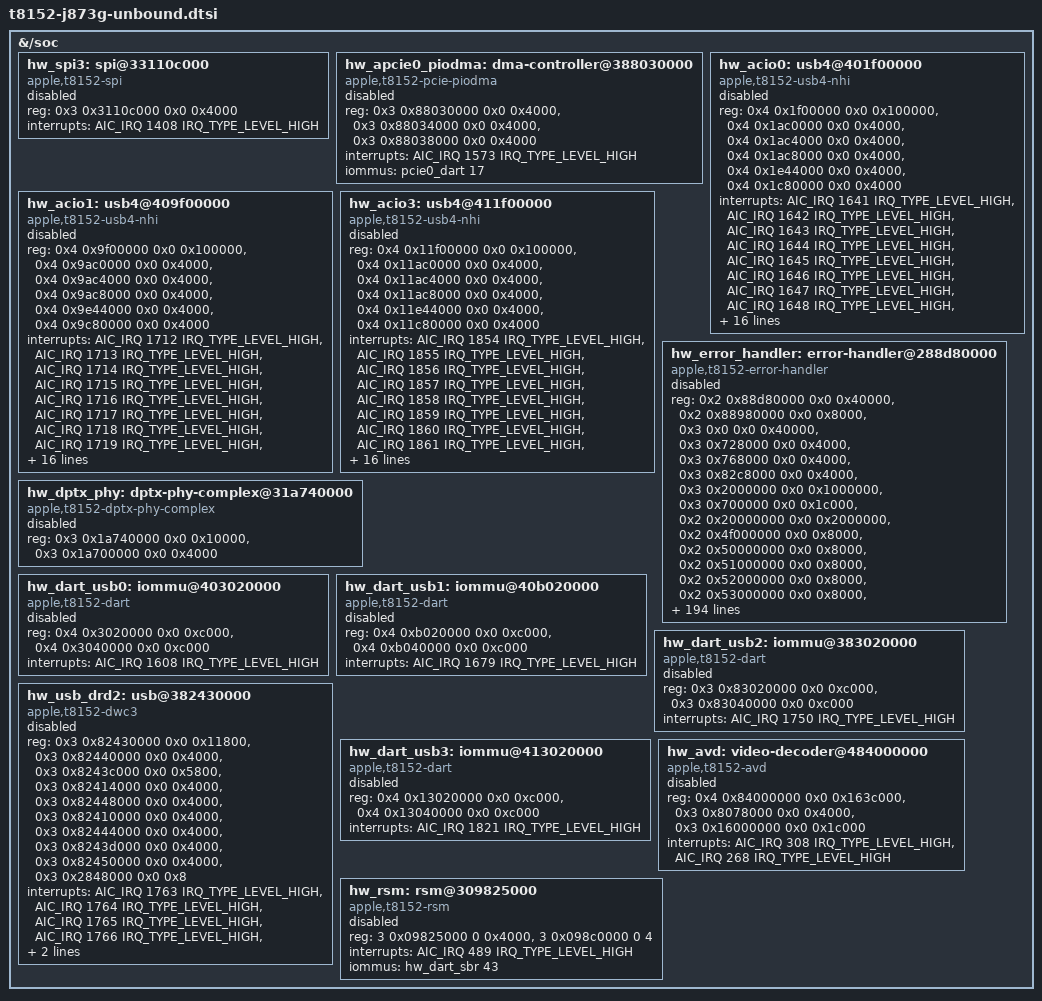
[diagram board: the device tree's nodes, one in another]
#include "t8152-peripherals.dtsi"

// SPDX-License-Identifier: GPL-2.0+ OR MIT
/* Register and interrupt resources; ownership-sensitive blocks stay disabled. */

&{/soc} {

	hw_spi3: spi@33110c000 {
		compatible = "apple,t8152-spi", "apple,spi";
		reg = <0x3 0x3110c000 0x0 0x4000>;
		interrupts = <AIC_IRQ 1408 IRQ_TYPE_LEVEL_HIGH>;
		status = "disabled";
	};

	hw_apcie0_piodma: dma-controller@388030000 {
		compatible = "apple,t8152-pcie-piodma", "apple,pcie-piodma";
		reg = <0x3 0x88030000 0x0 0x4000>,
		      <0x3 0x88034000 0x0 0x4000>,
		      <0x3 0x88038000 0x0 0x4000>;
		interrupts = <AIC_IRQ 1573 IRQ_TYPE_LEVEL_HIGH>;
		iommus = <&pcie0_dart 17>;
		status = "disabled";
	};

	hw_acio0: usb4@401f00000 {
		compatible = "apple,t8152-usb4-nhi", "apple,usb4-nhi";
		reg = <0x4 0x1f00000 0x0 0x100000>,
		      <0x4 0x1ac0000 0x0 0x4000>,
		      <0x4 0x1ac4000 0x0 0x4000>,
		      <0x4 0x1ac8000 0x0 0x4000>,
		      <0x4 0x1e44000 0x0 0x4000>,
		      <0x4 0x1c80000 0x0 0x4000>;
		interrupts = <AIC_IRQ 1641 IRQ_TYPE_LEVEL_HIGH>,
			     <AIC_IRQ 1642 IRQ_TYPE_LEVEL_HIGH>,
			     <AIC_IRQ 1643 IRQ_TYPE_LEVEL_HIGH>,
			     <AIC_IRQ 1644 IRQ_TYPE_LEVEL_HIGH>,
			     <AIC_IRQ 1645 IRQ_TYPE_LEVEL_HIGH>,
			     <AIC_IRQ 1646 IRQ_TYPE_LEVEL_HIGH>,
			     <AIC_IRQ 1647 IRQ_TYPE_LEVEL_HIGH>,
			     <AIC_IRQ 1648 IRQ_TYPE_LEVEL_HIGH>,
			     <AIC_IRQ 1649 IRQ_TYPE_LEVEL_HIGH>,
			     <AIC_IRQ 1650 IRQ_TYPE_LEVEL_HIGH>,
			     <AIC_IRQ 1651 IRQ_TYPE_LEVEL_HIGH>,
			     <AIC_IRQ 1652 IRQ_TYPE_LEVEL_HIGH>,
			     <AIC_IRQ 1629 IRQ_TYPE_LEVEL_HIGH>,
			     <AIC_IRQ 1630 IRQ_TYPE_LEVEL_HIGH>,
			     <AIC_IRQ 1631 IRQ_TYPE_LEVEL_HIGH>,
			     <AIC_IRQ 1632 IRQ_TYPE_LEVEL_HIGH>,
			     <AIC_IRQ 1633 IRQ_TYPE_LEVEL_HIGH>,
			     <AIC_IRQ 1634 IRQ_TYPE_LEVEL_HIGH>,
			     <AIC_IRQ 1635 IRQ_TYPE_LEVEL_HIGH>,
			     <AIC_IRQ 1636 IRQ_TYPE_LEVEL_HIGH>,
			     <AIC_IRQ 1637 IRQ_TYPE_LEVEL_HIGH>,
			     <AIC_IRQ 1638 IRQ_TYPE_LEVEL_HIGH>,
			     <AIC_IRQ 1639 IRQ_TYPE_LEVEL_HIGH>,
			     <AIC_IRQ 1640 IRQ_TYPE_LEVEL_HIGH>;
		status = "disabled";
	};

	hw_acio1: usb4@409f00000 {
		compatible = "apple,t8152-usb4-nhi", "apple,usb4-nhi";
		reg = <0x4 0x9f00000 0x0 0x100000>,
		      <0x4 0x9ac0000 0x0 0x4000>,
		      <0x4 0x9ac4000 0x0 0x4000>,
		      <0x4 0x9ac8000 0x0 0x4000>,
		      <0x4 0x9e44000 0x0 0x4000>,
		      <0x4 0x9c80000 0x0 0x4000>;
		interrupts = <AIC_IRQ 1712 IRQ_TYPE_LEVEL_HIGH>,
			     <AIC_IRQ 1713 IRQ_TYPE_LEVEL_HIGH>,
			     <AIC_IRQ 1714 IRQ_TYPE_LEVEL_HIGH>,
			     <AIC_IRQ 1715 IRQ_TYPE_LEVEL_HIGH>,
			     <AIC_IRQ 1716 IRQ_TYPE_LEVEL_HIGH>,
			     <AIC_IRQ 1717 IRQ_TYPE_LEVEL_HIGH>,
			     <AIC_IRQ 1718 IRQ_TYPE_LEVEL_HIGH>,
			     <AIC_IRQ 1719 IRQ_TYPE_LEVEL_HIGH>,
			     <AIC_IRQ 1720 IRQ_TYPE_LEVEL_HIGH>,
			     <AIC_IRQ 1721 IRQ_TYPE_LEVEL_HIGH>,
			     <AIC_IRQ 1722 IRQ_TYPE_LEVEL_HIGH>,
			     <AIC_IRQ 1723 IRQ_TYPE_LEVEL_HIGH>,
			     <AIC_IRQ 1700 IRQ_TYPE_LEVEL_HIGH>,
			     <AIC_IRQ 1701 IRQ_TYPE_LEVEL_HIGH>,
			     <AIC_IRQ 1702 IRQ_TYPE_LEVEL_HIGH>,
			     <AIC_IRQ 1703 IRQ_TYPE_LEVEL_HIGH>,
			     <AIC_IRQ 1704 IRQ_TYPE_LEVEL_HIGH>,
			     <AIC_IRQ 1705 IRQ_TYPE_LEVEL_HIGH>,
			     <AIC_IRQ 1706 IRQ_TYPE_LEVEL_HIGH>,
			     <AIC_IRQ 1707 IRQ_TYPE_LEVEL_HIGH>,
			     <AIC_IRQ 1708 IRQ_TYPE_LEVEL_HIGH>,
			     <AIC_IRQ 1709 IRQ_TYPE_LEVEL_HIGH>,
			     <AIC_IRQ 1710 IRQ_TYPE_LEVEL_HIGH>,
			     <AIC_IRQ 1711 IRQ_TYPE_LEVEL_HIGH>;
		status = "disabled";
	};

	hw_acio3: usb4@411f00000 {
		compatible = "apple,t8152-usb4-nhi", "apple,usb4-nhi";
		reg = <0x4 0x11f00000 0x0 0x100000>,
		      <0x4 0x11ac0000 0x0 0x4000>,
		      <0x4 0x11ac4000 0x0 0x4000>,
		      <0x4 0x11ac8000 0x0 0x4000>,
		      <0x4 0x11e44000 0x0 0x4000>,
		      <0x4 0x11c80000 0x0 0x4000>;
		interrupts = <AIC_IRQ 1854 IRQ_TYPE_LEVEL_HIGH>,
			     <AIC_IRQ 1855 IRQ_TYPE_LEVEL_HIGH>,
			     <AIC_IRQ 1856 IRQ_TYPE_LEVEL_HIGH>,
			     <AIC_IRQ 1857 IRQ_TYPE_LEVEL_HIGH>,
			     <AIC_IRQ 1858 IRQ_TYPE_LEVEL_HIGH>,
			     <AIC_IRQ 1859 IRQ_TYPE_LEVEL_HIGH>,
			     <AIC_IRQ 1860 IRQ_TYPE_LEVEL_HIGH>,
			     <AIC_IRQ 1861 IRQ_TYPE_LEVEL_HIGH>,
			     <AIC_IRQ 1862 IRQ_TYPE_LEVEL_HIGH>,
			     <AIC_IRQ 1863 IRQ_TYPE_LEVEL_HIGH>,
			     <AIC_IRQ 1864 IRQ_TYPE_LEVEL_HIGH>,
			     <AIC_IRQ 1865 IRQ_TYPE_LEVEL_HIGH>,
			     <AIC_IRQ 1842 IRQ_TYPE_LEVEL_HIGH>,
			     <AIC_IRQ 1843 IRQ_TYPE_LEVEL_HIGH>,
			     <AIC_IRQ 1844 IRQ_TYPE_LEVEL_HIGH>,
			     <AIC_IRQ 1845 IRQ_TYPE_LEVEL_HIGH>,
			     <AIC_IRQ 1846 IRQ_TYPE_LEVEL_HIGH>,
			     <AIC_IRQ 1847 IRQ_TYPE_LEVEL_HIGH>,
			     <AIC_IRQ 1848 IRQ_TYPE_LEVEL_HIGH>,
			     <AIC_IRQ 1849 IRQ_TYPE_LEVEL_HIGH>,
			     <AIC_IRQ 1850 IRQ_TYPE_LEVEL_HIGH>,
			     <AIC_IRQ 1851 IRQ_TYPE_LEVEL_HIGH>,
			     <AIC_IRQ 1852 IRQ_TYPE_LEVEL_HIGH>,
			     <AIC_IRQ 1853 IRQ_TYPE_LEVEL_HIGH>;
		status = "disabled";
	};

	hw_error_handler: error-handler@288d80000 {
		compatible = "apple,t8152-error-handler", "apple,soc-error-handler";
		reg = <0x2 0x88d80000 0x0 0x40000>,
		      <0x2 0x88980000 0x0 0x8000>,
		      <0x3 0x0 0x0 0x40000>,
		      <0x3 0x728000 0x0 0x4000>,
		      <0x3 0x768000 0x0 0x4000>,
		      <0x3 0x82c8000 0x0 0x4000>,
		      <0x3 0x2000000 0x0 0x1000000>,
		      <0x3 0x700000 0x0 0x1c000>,
		      <0x2 0x20000000 0x0 0x2000000>,
		      <0x2 0x4f000000 0x0 0x8000>,
		      <0x2 0x50000000 0x0 0x8000>,
		      <0x2 0x51000000 0x0 0x8000>,
		      <0x2 0x52000000 0x0 0x8000>,
		      <0x2 0x53000000 0x0 0x8000>,
		      <0x2 0x54000000 0x0 0x8000>,
		      <0x2 0x55000000 0x0 0x8000>,
		      <0x2 0x56000000 0x0 0x8000>,
		      <0x2 0x5f000000 0x0 0x1000000>,
		      <0x2 0x6f000000 0x0 0x1000000>,
		      <0x2 0x57000000 0x0 0x1000000>,
		      <0x2 0x58000000 0x0 0x1000000>,
		      <0x3 0x770000 0x0 0x4000>,
		      <0x3 0x771000 0x0 0x4000>,
		      <0x2 0x5b000000 0x0 0x24000>,
		      <0x3 0x3520000 0x0 0x4000>,
		      <0x3 0x3080000 0x0 0x18000>,
		      <0x3 0x3700000 0x0 0x8000>,
		      <0x3 0x3100000 0x0 0x20000>,
		      <0x3 0x440000 0x0 0x4000>,
		      <0x3 0x444000 0x0 0x4000>,
		      <0x3 0x18008000 0x0 0x4000>,
		      <0x3 0x1800c000 0x0 0x4000>,
		      <0x3 0x2fb48000 0x0 0x4000>,
		      <0x3 0x2fb4c000 0x0 0x4000>,
		      <0x4 0x19a08000 0x0 0x4000>,
		      <0x4 0x19a0c000 0x0 0x4000>,
		      <0x4 0x81a08000 0x0 0x4000>,
		      <0x4 0x81a0c000 0x0 0x4000>,
		      <0x2 0x86288000 0x0 0x4000>,
		      <0x2 0x8628c000 0x0 0x4000>,
		      <0x3 0x2a288000 0x0 0x4000>,
		      <0x3 0x2a28c000 0x0 0x4000>,
		      <0x5 0x2288000 0x0 0x4000>,
		      <0x5 0x228c000 0x0 0x4000>,
		      <0x4 0x85088000 0x0 0x4000>,
		      <0x4 0x8508c000 0x0 0x4000>,
		      <0x2 0x83088000 0x0 0x4000>,
		      <0x2 0x8308c000 0x0 0x4000>,
		      <0x5 0x80f48000 0x0 0x4000>,
		      <0x5 0x80f4c000 0x0 0x4000>,
		      <0x3 0x22008000 0x0 0x4000>,
		      <0x3 0x2200c000 0x0 0x4000>,
		      <0x3 0xa5108000 0x0 0x4000>,
		      <0x3 0xa510c000 0x0 0x4000>,
		      <0x3 0xa75c8000 0x0 0x4000>,
		      <0x3 0xa75cc000 0x0 0x4000>,
		      <0x3 0x31088000 0x0 0x4000>,
		      <0x3 0x3108c000 0x0 0x4000>,
		      <0x3 0xa1388000 0x0 0x4000>,
		      <0x3 0xa138c000 0x0 0x4000>,
		      <0x3 0x8d048000 0x0 0x4000>,
		      <0x3 0x8d04c000 0x0 0x4000>,
		      <0x4 0x5008000 0x0 0x4000>,
		      <0x4 0x500c000 0x0 0x4000>,
		      <0x4 0xd008000 0x0 0x4000>,
		      <0x4 0xd00c000 0x0 0x4000>,
		      <0x3 0x85008000 0x0 0x4000>,
		      <0x3 0x8500c000 0x0 0x4000>,
		      <0x4 0x15008000 0x0 0x4000>,
		      <0x4 0x1500c000 0x0 0x4000>,
		      <0x3 0x16000000 0x0 0x1c000>,
		      <0x3 0x2d700000 0x0 0xf4000>,
		      <0x3 0x2e7c8000 0x0 0x14000>,
		      <0x3 0x2e5c8000 0x0 0x14000>,
		      <0x3 0x10700000 0x0 0x14000>,
		      <0x3 0x11700000 0x0 0x14000>,
		      <0x3 0xc700000 0x0 0x14000>,
		      <0x4 0x19700000 0x0 0x14000>,
		      <0x4 0x81700000 0x0 0x14000>,
		      <0x2 0x86f00000 0x0 0x14000>,
		      <0x3 0x2af00000 0x0 0x14000>,
		      <0x5 0x2f00000 0x0 0x14000>,
		      <0x3 0xf00000 0x0 0x14000>,
		      <0x3 0x3148000 0x0 0x14000>,
		      <0x3 0x3a00000 0x0 0x1c000>,
		      <0x4 0x85548000 0x0 0x14000>,
		      <0x2 0x81700000 0x0 0x14000>,
		      <0x5 0x82700000 0x0 0x14000>,
		      <0x5 0x82f00000 0x0 0x14000>,
		      <0x3 0x21700000 0x0 0x14000>,
		      <0x3 0xa7488000 0x0 0x14000>,
		      <0x3 0x31f00000 0x0 0x14000>,
		      <0x3 0x14700000 0x0 0x14000>,
		      <0x4 0x18000000 0x0 0x8000>,
		      <0x4 0x80000000 0x0 0x8000>,
		      <0x2 0x87000000 0x0 0x8000>,
		      <0x3 0x2b000000 0x0 0x8000>,
		      <0x5 0x3000000 0x0 0x8000>,
		      <0x2 0x80000000 0x0 0x8000>,
		      <0x5 0x81000000 0x0 0x8000>,
		      <0x3 0x23000000 0x0 0x8000>,
		      <0x4 0x0 0x0 0x8000>,
		      <0x4 0x8000000 0x0 0x8000>,
		      <0x3 0x80000000 0x0 0x8000>,
		      <0x4 0x10000000 0x0 0x8000>,
		      <0x4 0x84000000 0x0 0x8000>,
		      <0x3 0x2c000000 0x0 0x8000>,
		      <0x3 0xa4000000 0x0 0x8000>,
		      <0x3 0x8e000000 0x0 0x8000>,
		      <0x3 0x30000000 0x0 0x8000>,
		      <0x3 0x19000000 0x0 0x8000>,
		      <0x3 0xa0000000 0x0 0x8000>;
		interrupts = <AIC_IRQ 546 IRQ_TYPE_LEVEL_HIGH>,
			     <AIC_IRQ 550 IRQ_TYPE_LEVEL_HIGH>,
			     <AIC_IRQ 545 IRQ_TYPE_LEVEL_HIGH>,
			     <AIC_IRQ 1226 IRQ_TYPE_LEVEL_HIGH>,
			     <AIC_IRQ 1220 IRQ_TYPE_LEVEL_HIGH>,
			     <AIC_IRQ 457 IRQ_TYPE_LEVEL_HIGH>,
			     <AIC_IRQ 459 IRQ_TYPE_LEVEL_HIGH>,
			     <AIC_IRQ 461 IRQ_TYPE_LEVEL_HIGH>,
			     <AIC_IRQ 463 IRQ_TYPE_LEVEL_HIGH>,
			     <AIC_IRQ 465 IRQ_TYPE_LEVEL_HIGH>,
			     <AIC_IRQ 468 IRQ_TYPE_LEVEL_HIGH>,
			     <AIC_IRQ 471 IRQ_TYPE_LEVEL_HIGH>,
			     <AIC_IRQ 474 IRQ_TYPE_LEVEL_HIGH>,
			     <AIC_IRQ 477 IRQ_TYPE_LEVEL_HIGH>,
			     <AIC_IRQ 480 IRQ_TYPE_LEVEL_HIGH>,
			     <AIC_IRQ 483 IRQ_TYPE_LEVEL_HIGH>,
			     <AIC_IRQ 486 IRQ_TYPE_LEVEL_HIGH>,
			     <AIC_IRQ 126 IRQ_TYPE_LEVEL_HIGH>,
			     <AIC_IRQ 127 IRQ_TYPE_LEVEL_HIGH>,
			     <AIC_IRQ 128 IRQ_TYPE_LEVEL_HIGH>,
			     <AIC_IRQ 129 IRQ_TYPE_LEVEL_HIGH>,
			     <AIC_IRQ 130 IRQ_TYPE_LEVEL_HIGH>,
			     <AIC_IRQ 131 IRQ_TYPE_LEVEL_HIGH>,
			     <AIC_IRQ 132 IRQ_TYPE_LEVEL_HIGH>,
			     <AIC_IRQ 133 IRQ_TYPE_LEVEL_HIGH>,
			     <AIC_IRQ 139 IRQ_TYPE_LEVEL_HIGH>,
			     <AIC_IRQ 138 IRQ_TYPE_LEVEL_HIGH>,
			     <AIC_IRQ 134 IRQ_TYPE_LEVEL_HIGH>,
			     <AIC_IRQ 135 IRQ_TYPE_LEVEL_HIGH>,
			     <AIC_IRQ 409 IRQ_TYPE_LEVEL_HIGH>,
			     <AIC_IRQ 136 IRQ_TYPE_LEVEL_HIGH>,
			     <AIC_IRQ 1234 IRQ_TYPE_LEVEL_HIGH>,
			     <AIC_IRQ 1202 IRQ_TYPE_LEVEL_HIGH>,
			     <AIC_IRQ 1204 IRQ_TYPE_LEVEL_HIGH>,
			     <AIC_IRQ 210 IRQ_TYPE_LEVEL_HIGH>,
			     <AIC_IRQ 536 IRQ_TYPE_LEVEL_HIGH>,
			     <AIC_IRQ 787 IRQ_TYPE_LEVEL_HIGH>,
			     <AIC_IRQ 835 IRQ_TYPE_LEVEL_HIGH>,
			     <AIC_IRQ 912 IRQ_TYPE_LEVEL_HIGH>,
			     <AIC_IRQ 1050 IRQ_TYPE_LEVEL_HIGH>,
			     <AIC_IRQ 1126 IRQ_TYPE_LEVEL_HIGH>,
			     <AIC_IRQ 1266 IRQ_TYPE_LEVEL_HIGH>,
			     <AIC_IRQ 1293 IRQ_TYPE_LEVEL_HIGH>,
			     <AIC_IRQ 1315 IRQ_TYPE_LEVEL_HIGH>,
			     <AIC_IRQ 1343 IRQ_TYPE_LEVEL_HIGH>,
			     <AIC_IRQ 1355 IRQ_TYPE_LEVEL_HIGH>,
			     <AIC_IRQ 1365 IRQ_TYPE_LEVEL_HIGH>,
			     <AIC_IRQ 1430 IRQ_TYPE_LEVEL_HIGH>,
			     <AIC_IRQ 1559 IRQ_TYPE_LEVEL_HIGH>,
			     <AIC_IRQ 1565 IRQ_TYPE_LEVEL_HIGH>,
			     <AIC_IRQ 1606 IRQ_TYPE_LEVEL_HIGH>,
			     <AIC_IRQ 1677 IRQ_TYPE_LEVEL_HIGH>,
			     <AIC_IRQ 1748 IRQ_TYPE_LEVEL_HIGH>,
			     <AIC_IRQ 1819 IRQ_TYPE_LEVEL_HIGH>,
			     <AIC_IRQ 214 IRQ_TYPE_LEVEL_HIGH>,
			     <AIC_IRQ 510 IRQ_TYPE_LEVEL_HIGH>,
			     <AIC_IRQ 519 IRQ_TYPE_LEVEL_HIGH>,
			     <AIC_IRQ 525 IRQ_TYPE_LEVEL_HIGH>,
			     <AIC_IRQ 625 IRQ_TYPE_LEVEL_HIGH>,
			     <AIC_IRQ 632 IRQ_TYPE_LEVEL_HIGH>,
			     <AIC_IRQ 763 IRQ_TYPE_LEVEL_HIGH>,
			     <AIC_IRQ 784 IRQ_TYPE_LEVEL_HIGH>,
			     <AIC_IRQ 832 IRQ_TYPE_LEVEL_HIGH>,
			     <AIC_IRQ 871 IRQ_TYPE_LEVEL_HIGH>,
			     <AIC_IRQ 1009 IRQ_TYPE_LEVEL_HIGH>,
			     <AIC_IRQ 1085 IRQ_TYPE_LEVEL_HIGH>,
			     <AIC_IRQ 1159 IRQ_TYPE_LEVEL_HIGH>,
			     <AIC_IRQ 1237 IRQ_TYPE_LEVEL_HIGH>,
			     <AIC_IRQ 1245 IRQ_TYPE_LEVEL_HIGH>,
			     <AIC_IRQ 1254 IRQ_TYPE_LEVEL_HIGH>,
			     <AIC_IRQ 1276 IRQ_TYPE_LEVEL_HIGH>,
			     <AIC_IRQ 1318 IRQ_TYPE_LEVEL_HIGH>,
			     <AIC_IRQ 1324 IRQ_TYPE_LEVEL_HIGH>,
			     <AIC_IRQ 1345 IRQ_TYPE_LEVEL_HIGH>,
			     <AIC_IRQ 1378 IRQ_TYPE_LEVEL_HIGH>,
			     <AIC_IRQ 1395 IRQ_TYPE_LEVEL_HIGH>,
			     <AIC_IRQ 1499 IRQ_TYPE_LEVEL_HIGH>,
			     <AIC_IRQ 790 IRQ_TYPE_LEVEL_HIGH>,
			     <AIC_IRQ 838 IRQ_TYPE_LEVEL_HIGH>,
			     <AIC_IRQ 888 IRQ_TYPE_LEVEL_HIGH>,
			     <AIC_IRQ 1026 IRQ_TYPE_LEVEL_HIGH>,
			     <AIC_IRQ 1102 IRQ_TYPE_LEVEL_HIGH>,
			     <AIC_IRQ 1281 IRQ_TYPE_LEVEL_HIGH>,
			     <AIC_IRQ 1302 IRQ_TYPE_LEVEL_HIGH>,
			     <AIC_IRQ 1340 IRQ_TYPE_LEVEL_HIGH>,
			     <AIC_IRQ 1598 IRQ_TYPE_LEVEL_HIGH>,
			     <AIC_IRQ 1669 IRQ_TYPE_LEVEL_HIGH>,
			     <AIC_IRQ 1740 IRQ_TYPE_LEVEL_HIGH>,
			     <AIC_IRQ 1811 IRQ_TYPE_LEVEL_HIGH>,
			     <AIC_IRQ 1261 IRQ_TYPE_LEVEL_HIGH>,
			     <AIC_IRQ 535 IRQ_TYPE_LEVEL_HIGH>,
			     <AIC_IRQ 1353 IRQ_TYPE_LEVEL_HIGH>,
			     <AIC_IRQ 1561 IRQ_TYPE_LEVEL_HIGH>,
			     <AIC_IRQ 1427 IRQ_TYPE_LEVEL_HIGH>,
			     <AIC_IRQ 212 IRQ_TYPE_LEVEL_HIGH>,
			     <AIC_IRQ 1512 IRQ_TYPE_LEVEL_HIGH>;
		status = "disabled";
	};

	hw_dptx_phy: dptx-phy-complex@31a740000 {
		compatible = "apple,t8152-dptx-phy-complex", "apple,dptx-phy-complex";
		reg = <0x3 0x1a740000 0x0 0x10000>,
		      <0x3 0x1a700000 0x0 0x4000>;
		status = "disabled";
	};

	hw_dart_usb0: iommu@403020000 {
		compatible = "apple,t8152-dart", "apple,dart";
		reg = <0x4 0x3020000 0x0 0xc000>,
		      <0x4 0x3040000 0x0 0xc000>;
		#iommu-cells = <1>;
		interrupts = <AIC_IRQ 1608 IRQ_TYPE_LEVEL_HIGH>;
		status = "disabled";
	};

	hw_dart_usb1: iommu@40b020000 {
		compatible = "apple,t8152-dart", "apple,dart";
		reg = <0x4 0xb020000 0x0 0xc000>,
		      <0x4 0xb040000 0x0 0xc000>;
		#iommu-cells = <1>;
		interrupts = <AIC_IRQ 1679 IRQ_TYPE_LEVEL_HIGH>;
		status = "disabled";
	};

	hw_dart_usb2: iommu@383020000 {
		compatible = "apple,t8152-dart", "apple,dart";
		reg = <0x3 0x83020000 0x0 0xc000>,
		      <0x3 0x83040000 0x0 0xc000>;
		#iommu-cells = <1>;
		interrupts = <AIC_IRQ 1750 IRQ_TYPE_LEVEL_HIGH>;
		status = "disabled";
	};

	hw_usb_drd2: usb@382430000 {
		compatible = "apple,t8152-dwc3", "apple,dwc3";
		reg = <0x3 0x82430000 0x0 0x11800>,
		      <0x3 0x82440000 0x0 0x4000>,
		      <0x3 0x8243c000 0x0 0x5800>,
		      <0x3 0x82414000 0x0 0x4000>,
		      <0x3 0x82448000 0x0 0x4000>,
		      <0x3 0x82410000 0x0 0x4000>,
		      <0x3 0x82444000 0x0 0x4000>,
		      <0x3 0x8243d000 0x0 0x4000>,
		      <0x3 0x82450000 0x0 0x4000>,
		      <0x3 0x2848000 0x0 0x8>;
		interrupts = <AIC_IRQ 1763 IRQ_TYPE_LEVEL_HIGH>,
			     <AIC_IRQ 1764 IRQ_TYPE_LEVEL_HIGH>,
			     <AIC_IRQ 1765 IRQ_TYPE_LEVEL_HIGH>,
			     <AIC_IRQ 1766 IRQ_TYPE_LEVEL_HIGH>,
			     <AIC_IRQ 1737 IRQ_TYPE_LEVEL_HIGH>;
		iommus = <&hw_dart_usb2 1>;
		status = "disabled";
	};

	hw_dart_usb3: iommu@413020000 {
		compatible = "apple,t8152-dart", "apple,dart";
		reg = <0x4 0x13020000 0x0 0xc000>,
		      <0x4 0x13040000 0x0 0xc000>;
		#iommu-cells = <1>;
		interrupts = <AIC_IRQ 1821 IRQ_TYPE_LEVEL_HIGH>;
		status = "disabled";
	};

	hw_avd: video-decoder@484000000 {
		compatible = "apple,t8152-avd", "apple,avd";
		reg = <0x4 0x84000000 0x0 0x163c000>,
		      <0x3 0x8078000 0x0 0x4000>,
		      <0x3 0x16000000 0x0 0x1c000>;
		interrupts = <AIC_IRQ 308 IRQ_TYPE_LEVEL_HIGH>,
			     <AIC_IRQ 268 IRQ_TYPE_LEVEL_HIGH>;
		status = "disabled";
	};


};

/* Static template resource omitted from the live snapshot. */
&{/soc} {
	hw_rsm: rsm@309825000 {
		compatible = "apple,t8152-rsm", "apple,rsm";
		reg = <3 0x09825000 0 0x4000>, <3 0x098c0000 0 4>;
		interrupts = <AIC_IRQ 489 IRQ_TYPE_LEVEL_HIGH>;
		iommus = <&hw_dart_sbr 43>;
		status = "disabled";
	};
};
